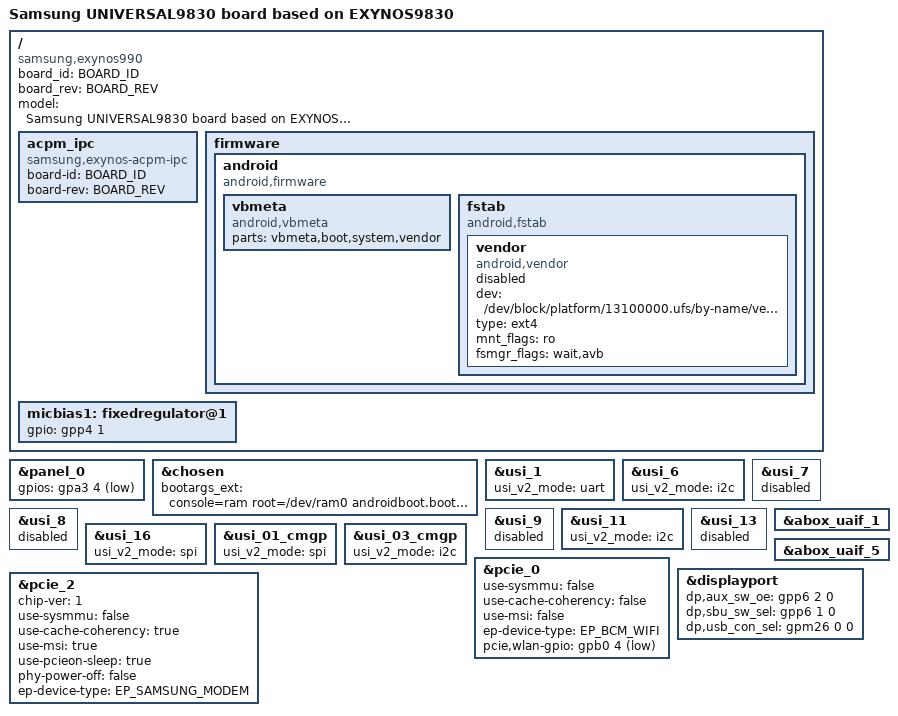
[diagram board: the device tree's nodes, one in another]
/*
 * SAMSUNG EXYNOS9820 board device tree source
 *
 * Copyright (c) 2019 Samsung Electronics Co., Ltd.
 *		http://www.samsung.com
 *
 * This program is free software; you can redistribute it and/or modify
 * it under the terms of the GNU General Public License version 2 as
 * published by the Free Software Foundation.
*/

/dts-v1/;
/plugin/;
#include "exynos9830-universal9830_power_r10.dtsi"
#include "exynos9830-universal9830_common.dtsi"
#include "exynos9830-universal9830-camera_r05.dtsi"
#include "exynos9830-universal9830-cp-s5123-sipc.dtsi"

#define BOARD_ID	0x10
#define BOARD_REV	0x10

/ {
	compatible = "samsung,exynos990", "samsung,UNIVERSAL990";
	board_id = <BOARD_ID>;
	board_rev = <BOARD_REV>;

	fragment@model {
		target-path = "/";
		__overlay__ {
			#address-cells = <2>;
			#size-cells = <1>;

			model = "Samsung UNIVERSAL9830 board based on EXYNOS9830";

			acpm_ipc {
				compatible = "samsung,exynos-acpm-ipc";
				board-id = <BOARD_ID>;
				board-rev = <BOARD_REV>;
			};

			firmware {
				android: android {
					compatible = "android,firmware";
					vbmeta {
						compatible = "android,vbmeta";
						parts = "vbmeta,boot,system,vendor";
					};
					fstab {
						compatible = "android,fstab";
						vendor: vendor {
							compatible = "android,vendor";
							dev = "/dev/block/platform/13100000.ufs/by-name/vendor";
							type = "ext4";
							mnt_flags = "ro";
							fsmgr_flags = "wait,avb";
							status = "disabled";
						};
					};
				};
			};

			micbias1: fixedregulator@1 {
				gpio = <&gpp4 1 0>;
			};
		}; /* end of __overlay__ */
	}; /* end of fragment */
}; /* end of root */

&panel_0 {
	/* reset, power */
	gpios = <&gpa3 4 0x1>;
};

&chosen {
	bootargs_ext = "console=ram root=/dev/ram0 androidboot.boot_devices=13100000.ufs";
};

&usi_1 {
	usi_v2_mode = "uart";
	status = "okay";
};

&usi_6 {
	usi_v2_mode = "i2c";
	status = "okay";
};

&usi_7 {
	status = "disabled";
};

&usi_8 {
	status = "disabled";
};

&usi_9 {
	status = "disabled";
};

&usi_11 {
	usi_v2_mode = "i2c";
	status = "okay";
};

&usi_13 {
	status = "disabled";
};

&usi_16 {
	usi_v2_mode = "spi";
	status = "okay";
};

&usi_01_cmgp {
	usi_v2_mode = "spi";
	status = "okay";
};

&usi_03_cmgp {
	usi_v2_mode = "i2c";
	status = "okay";
};

/* Removed pinctrl-names to prevent duplicating request */
&abox_uaif_1 {
	pinctrl-names;
};

&abox_uaif_5 {
	pinctrl-names;
};

&pcie_0 {
	status = "okay";
	use-sysmmu = "false";
	use-cache-coherency = "false";
	use-msi = "false";
	ep-device-type = <EP_BCM_WIFI>;
	pcie,wlan-gpio = <&gpb0 4 0x1 /* WLAN_EN */ >;
};

&pcie_2 {
    status = "okay";
    chip-ver = <1>;
    use-sysmmu = "false";
    use-cache-coherency = "true";
    use-msi = "true";
    use-pcieon-sleep = "true";
    phy-power-off = "false";
    ep-device-type = <EP_SAMSUNG_MODEM>;
};

&displayport {
	status = "okay";
	dp,aux_sw_oe = <&gpp6 2 0>;
	dp,sbu_sw_sel = <&gpp6 1 0>;
	dp,usb_con_sel = <&gpm26 0 0>;

	pinctrl-names = "default";
};

